AUTOSAR XML (schema 4-2-2)
package /STELLANTIS/EPT/SASWCs
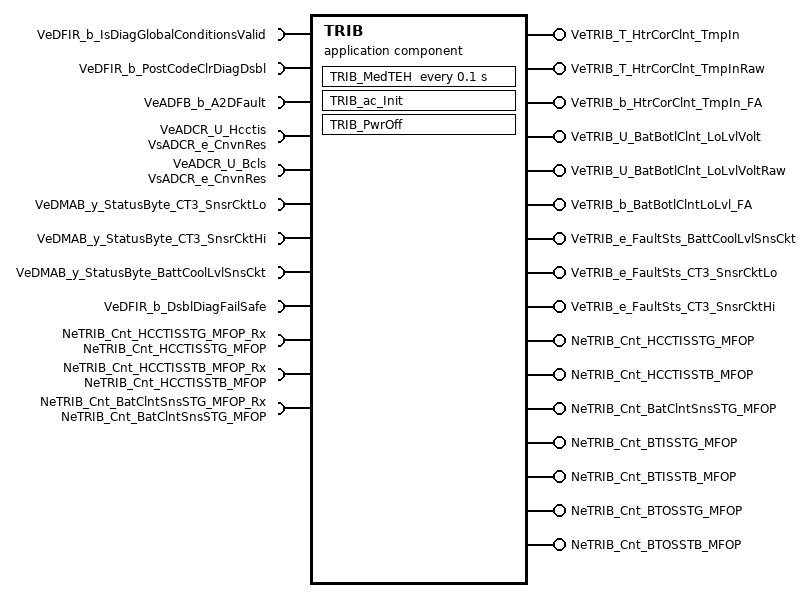
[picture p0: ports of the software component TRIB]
  application sw component type TRIB
    9 x require port:
      VeDFIR_b_IsDiagGlobalConditionsValid: variation-point={short-label=vpVeDFIR_b_IsDiagGlobalConditionsValid, sw-syscond=1}, nonqueued-receiver-com-spec{data-element=Value, init-value=0}, required-interface=VeDFIR_b_IsDiagGlobalConditionsValid
      VeDFIR_b_PostCodeClrDiagDsbl: variation-point={short-label=vpVeDFIR_b_PostCodeClrDiagDsbl, sw-syscond=1}, nonqueued-receiver-com-spec{data-element=Value, init-value=0}, required-interface=VeDFIR_b_PostCodeClrDiagDsbl
      VeADFB_b_A2DFault: variation-point={short-label=vpVeADFB_b_A2DFault, sw-syscond=1}, nonqueued-receiver-com-spec{data-element=Value, init-value=0}, required-interface=VeADFB_b_A2DFault
      VeADCR_U_Hcctis: variation-point={short-label=vpVeADCR_U_Hcctis, sw-syscond=1}, nonqueued-receiver-com-spec{data-element=VsADCR_e_CnvnRes, init-value={short-label=DefaultInitValue_IDTRAdcInpResData, fields=[0, 0]}}, required-interface=VsADCR_e_CnvnRes
      VeADCR_U_Bcls: variation-point={short-label=vpVeADCR_U_Bcls, sw-syscond=1}, nonqueued-receiver-com-spec{data-element=VsADCR_e_CnvnRes, init-value={short-label=DefaultInitValue_IDTRAdcInpResData, fields=[0, 0]}}, required-interface=VsADCR_e_CnvnRes
      VeDMAB_y_StatusByte_CT3_SnsrCktLo: variation-point={short-label=vpVeDMAB_y_StatusByte_CT3_SnsrCktLo, sw-syscond=1}, nonqueued-receiver-com-spec{data-element=Value, init-value=0}, required-interface=VeDMAB_y_StatusByte_CT3_SnsrCktLo
      VeDMAB_y_StatusByte_CT3_SnsrCktHi: variation-point={short-label=vpVeDMAB_y_StatusByte_CT3_SnsrCktHi, sw-syscond=1}, nonqueued-receiver-com-spec{data-element=Value, init-value=0}, required-interface=VeDMAB_y_StatusByte_CT3_SnsrCktHi
      VeDMAB_y_StatusByte_BattCoolLvlSnsCkt: variation-point={short-label=vpVeDMAB_y_StatusByte_BattCoolLvlSnsCkt, sw-syscond=1}, nonqueued-receiver-com-spec{data-element=Value, init-value=0}, required-interface=VeDMAB_y_StatusByte_BattCoolLvlSnsCkt
      VeDFIR_b_DsblDiagFailSafe: variation-point={short-label=vpVeDFIR_b_DsblDiagFailSafe, sw-syscond=1}, nonqueued-receiver-com-spec{data-element=Value, init-value=0}, required-interface=VeDFIR_b_DsblDiagFailSafe
    9 x provide port:
      VeTRIB_T_HtrCorClnt_TmpIn: variation-point={short-label=vpVeTRIB_T_HtrCorClnt_TmpIn, sw-syscond=1}, nonqueued-sender-com-spec{data-element=Value, init-value=0}, provided-interface=VeTRIB_T_HtrCorClnt_TmpIn
      VeTRIB_T_HtrCorClnt_TmpInRaw: variation-point={short-label=vpVeTRIB_T_HtrCorClnt_TmpInRaw, sw-syscond=1}, nonqueued-sender-com-spec{data-element=Value, init-value=0}, provided-interface=VeTRIB_T_HtrCorClnt_TmpInRaw
      VeTRIB_b_HtrCorClnt_TmpIn_FA: variation-point={short-label=vpVeTRIB_b_HtrCorClnt_TmpIn_FA, sw-syscond=1}, nonqueued-sender-com-spec{data-element=Value, init-value=0}, provided-interface=VeTRIB_b_HtrCorClnt_TmpIn_FA
      VeTRIB_U_BatBotlClnt_LoLvlVolt: variation-point={short-label=vpVeTRIB_U_BatBotlClnt_LoLvlVolt, sw-syscond=1}, nonqueued-sender-com-spec{data-element=Value, init-value=0}, provided-interface=VeTRIB_U_BatBotlClnt_LoLvlVolt
      VeTRIB_U_BatBotlClnt_LoLvlVoltRaw: variation-point={short-label=vpVeTRIB_U_BatBotlClnt_LoLvlVoltRaw, sw-syscond=1}, nonqueued-sender-com-spec{data-element=Value, init-value=0}, provided-interface=VeTRIB_U_BatBotlClnt_LoLvlVoltRaw
      VeTRIB_b_BatBotlClntLoLvl_FA: variation-point={short-label=vpVeTRIB_b_BatBotlClntLoLvl_FA, sw-syscond=1}, nonqueued-sender-com-spec{data-element=Value, init-value=0}, provided-interface=VeTRIB_b_BatBotlClntLoLvl_FA
      VeTRIB_e_FaultSts_BattCoolLvlSnsCkt: variation-point={short-label=vpVeTRIB_e_FaultSts_BattCoolLvlSnsCkt, sw-syscond=1}, nonqueued-sender-com-spec{data-element=Value, init-value=CeDFIB_e_Init}, provided-interface=VeTRIB_e_FaultSts_BattCoolLvlSnsCkt
      VeTRIB_e_FaultSts_CT3_SnsrCktLo: variation-point={short-label=vpVeTRIB_e_FaultSts_CT3_SnsrCktLo, sw-syscond=1}, nonqueued-sender-com-spec{data-element=Value, init-value=CeDFIB_e_Init}, provided-interface=VeTRIB_e_FaultSts_CT3_SnsrCktLo
      VeTRIB_e_FaultSts_CT3_SnsrCktHi: variation-point={short-label=vpVeTRIB_e_FaultSts_CT3_SnsrCktHi, sw-syscond=1}, nonqueued-sender-com-spec{data-element=Value, init-value=CeDFIB_e_Init}, provided-interface=VeTRIB_e_FaultSts_CT3_SnsrCktHi
    require port NeTRIB_Cnt_HCCTISSTG_MFOP_Rx: variation-point={short-label=vpNeTRIB_Cnt_HCCTISSTG_MFOP_Rx, sw-syscond=1}, nv-require-com-spec{init-value=0, variable=NeTRIB_Cnt_HCCTISSTG_MFOP}, required-interface=NeTRIB_Cnt_HCCTISSTG_MFOP
    require port NeTRIB_Cnt_HCCTISSTB_MFOP_Rx: variation-point={short-label=vpNeTRIB_Cnt_HCCTISSTB_MFOP_Rx, sw-syscond=1}, nv-require-com-spec{init-value=0, variable=NeTRIB_Cnt_HCCTISSTB_MFOP}, required-interface=NeTRIB_Cnt_HCCTISSTB_MFOP
    require port NeTRIB_Cnt_BatClntSnsSTG_MFOP_Rx: variation-point={short-label=vpNeTRIB_Cnt_BatClntSnsSTG_MFOP_Rx, sw-syscond=1}, nv-require-com-spec{init-value=0, variable=NeTRIB_Cnt_BatClntSnsSTG_MFOP}, required-interface=NeTRIB_Cnt_BatClntSnsSTG_MFOP
    7 x provide port:
      NeTRIB_Cnt_HCCTISSTG_MFOP: nv-provide-com-spec{ram-block-init-value=0, variable=NeTRIB_Cnt_HCCTISSTG_MFOP}, provided-interface=NeTRIB_Cnt_HCCTISSTG_MFOP
      NeTRIB_Cnt_HCCTISSTB_MFOP: nv-provide-com-spec{ram-block-init-value=0, variable=NeTRIB_Cnt_HCCTISSTB_MFOP}, provided-interface=NeTRIB_Cnt_HCCTISSTB_MFOP
      NeTRIB_Cnt_BatClntSnsSTG_MFOP: nv-provide-com-spec{ram-block-init-value=0, variable=NeTRIB_Cnt_BatClntSnsSTG_MFOP}, provided-interface=NeTRIB_Cnt_BatClntSnsSTG_MFOP
      NeTRIB_Cnt_BTISSTG_MFOP: nv-provide-com-spec{ram-block-init-value=0, variable=NeTRIB_Cnt_BTISSTG_MFOP}, provided-interface=NeTRIB_Cnt_BTISSTG_MFOP
      NeTRIB_Cnt_BTISSTB_MFOP: nv-provide-com-spec{ram-block-init-value=0, variable=NeTRIB_Cnt_BTISSTB_MFOP}, provided-interface=NeTRIB_Cnt_BTISSTB_MFOP
      NeTRIB_Cnt_BTOSSTG_MFOP: nv-provide-com-spec{ram-block-init-value=0, variable=NeTRIB_Cnt_BTOSSTG_MFOP}, provided-interface=NeTRIB_Cnt_BTOSSTG_MFOP
      NeTRIB_Cnt_BTOSSTB_MFOP: nv-provide-com-spec{ram-block-init-value=0, variable=NeTRIB_Cnt_BTOSSTB_MFOP}, provided-interface=NeTRIB_Cnt_BTOSSTB_MFOP
    behavior IB_TRIB: data-type-mapping=[msADTtoIDTMapping, ADTtoIDTMapping], handle-termination-and-restart=NO-SUPPORT
      timing event Event_MedTEH: start-on-event=TRIB_MedTEH, period=0.1
      init event Event_TRIB_ac_Init: start-on-event=TRIB_ac_Init
      init event Event_PwrOff: start-on-event=TRIB_PwrOff
      runnable TRIB_ac_Init
        data-receive-point-by-arguments:
          access IN_NeTRIB_Cnt_BatClntSnsSTG_MFOP_Rx_NeTRIB_Cnt_BatClntSnsSTG_MFOP: accessed-variable=NeTRIB_Cnt_BatClntSnsSTG_MFOP_Rx.NeTRIB_Cnt_BatClntSnsSTG_MFOP, variation-point={short-label=vpIN_NeTRIB_Cnt_BatClntSnsSTG_MFOP_Rx_NeTRIB_Cnt_BatClntSnsSTG_MFOP, sw-syscond=1}
          access IN_NeTRIB_Cnt_HCCTISSTB_MFOP_Rx_NeTRIB_Cnt_HCCTISSTB_MFOP: accessed-variable=NeTRIB_Cnt_HCCTISSTB_MFOP_Rx.NeTRIB_Cnt_HCCTISSTB_MFOP, variation-point={short-label=vpIN_NeTRIB_Cnt_HCCTISSTB_MFOP_Rx_NeTRIB_Cnt_HCCTISSTB_MFOP, sw-syscond=1}
          access IN_NeTRIB_Cnt_HCCTISSTG_MFOP_Rx_NeTRIB_Cnt_HCCTISSTG_MFOP: accessed-variable=NeTRIB_Cnt_HCCTISSTG_MFOP_Rx.NeTRIB_Cnt_HCCTISSTG_MFOP, variation-point={short-label=vpIN_NeTRIB_Cnt_HCCTISSTG_MFOP_Rx_NeTRIB_Cnt_HCCTISSTG_MFOP, sw-syscond=1}
        data-send-points:
          7 x access:
            OUT_VeTRIB_T_HtrCorClnt_TmpIn_Value: accessed-variable=VeTRIB_T_HtrCorClnt_TmpIn.Value, variation-point={short-label=vpOUT_VeTRIB_T_HtrCorClnt_TmpIn_Value, sw-syscond=1}
            OUT_VeTRIB_T_HtrCorClnt_TmpInRaw_Value: accessed-variable=VeTRIB_T_HtrCorClnt_TmpInRaw.Value, variation-point={short-label=vpOUT_VeTRIB_T_HtrCorClnt_TmpInRaw_Value, sw-syscond=1}
            OUT_VeTRIB_e_FaultSts_CT3_SnsrCktLo_Value: accessed-variable=VeTRIB_e_FaultSts_CT3_SnsrCktLo.Value, variation-point={short-label=vpOUT_VeTRIB_e_FaultSts_CT3_SnsrCktLo_Value, sw-syscond=1}
            OUT_VeTRIB_e_FaultSts_CT3_SnsrCktHi_Value: accessed-variable=VeTRIB_e_FaultSts_CT3_SnsrCktHi.Value, variation-point={short-label=vpOUT_VeTRIB_e_FaultSts_CT3_SnsrCktHi_Value, sw-syscond=1}
            OUT_VeTRIB_U_BatBotlClnt_LoLvlVolt_Value: accessed-variable=VeTRIB_U_BatBotlClnt_LoLvlVolt.Value, variation-point={short-label=vpOUT_VeTRIB_U_BatBotlClnt_LoLvlVolt_Value, sw-syscond=1}
            OUT_VeTRIB_U_BatBotlClnt_LoLvlVoltRaw_Value: accessed-variable=VeTRIB_U_BatBotlClnt_LoLvlVoltRaw.Value, variation-point={short-label=vpOUT_VeTRIB_U_BatBotlClnt_LoLvlVoltRaw_Value, sw-syscond=1}
            OUT_VeTRIB_e_FaultSts_BattCoolLvlSnsCkt_Value: accessed-variable=VeTRIB_e_FaultSts_BattCoolLvlSnsCkt.Value, variation-point={short-label=vpOUT_VeTRIB_e_FaultSts_BattCoolLvlSnsCkt_Value, sw-syscond=1}
      runnable TRIB_MedTEH
        data-receive-point-by-arguments:
          9 x access:
            IN_VeADCR_U_Bcls_VsADCR_e_CnvnRes: accessed-variable=VeADCR_U_Bcls.VsADCR_e_CnvnRes, variation-point={short-label=vpIN_VeADCR_U_Bcls_VsADCR_e_CnvnRes, sw-syscond=1}
            IN_VeADCR_U_Hcctis_VsADCR_e_CnvnRes: accessed-variable=VeADCR_U_Hcctis.VsADCR_e_CnvnRes, variation-point={short-label=vpIN_VeADCR_U_Hcctis_VsADCR_e_CnvnRes, sw-syscond=1}
            IN_VeADFB_b_A2DFault_Value: accessed-variable=VeADFB_b_A2DFault.Value, variation-point={short-label=vpIN_VeADFB_b_A2DFault_Value, sw-syscond=1}
            IN_VeDFIR_b_DsblDiagFailSafe_Value: accessed-variable=VeDFIR_b_DsblDiagFailSafe.Value, variation-point={short-label=vpIN_VeDFIR_b_DsblDiagFailSafe_Value, sw-syscond=1}
            IN_VeDFIR_b_IsDiagGlobalConditionsValid_Value: accessed-variable=VeDFIR_b_IsDiagGlobalConditionsValid.Value, variation-point={short-label=vpIN_VeDFIR_b_IsDiagGlobalConditionsValid_Value, sw-syscond=1}
            IN_VeDFIR_b_PostCodeClrDiagDsbl_Value: accessed-variable=VeDFIR_b_PostCodeClrDiagDsbl.Value, variation-point={short-label=vpIN_VeDFIR_b_PostCodeClrDiagDsbl_Value, sw-syscond=1}
            IN_VeDMAB_y_StatusByte_BattCoolLvlSnsCkt_Value: accessed-variable=VeDMAB_y_StatusByte_BattCoolLvlSnsCkt.Value, variation-point={short-label=vpIN_VeDMAB_y_StatusByte_BattCoolLvlSnsCkt_Value, sw-syscond=1}
            IN_VeDMAB_y_StatusByte_CT3_SnsrCktHi_Value: accessed-variable=VeDMAB_y_StatusByte_CT3_SnsrCktHi.Value, variation-point={short-label=vpIN_VeDMAB_y_StatusByte_CT3_SnsrCktHi_Value, sw-syscond=1}
            IN_VeDMAB_y_StatusByte_CT3_SnsrCktLo_Value: accessed-variable=VeDMAB_y_StatusByte_CT3_SnsrCktLo.Value, variation-point={short-label=vpIN_VeDMAB_y_StatusByte_CT3_SnsrCktLo_Value, sw-syscond=1}
        data-send-points:
          9 x access:
            OUT_VeTRIB_b_HtrCorClnt_TmpIn_FA_Value: accessed-variable=VeTRIB_b_HtrCorClnt_TmpIn_FA.Value, variation-point={short-label=vpOUT_VeTRIB_b_HtrCorClnt_TmpIn_FA_Value, sw-syscond=1}
            OUT_VeTRIB_T_HtrCorClnt_TmpInRaw_Value: accessed-variable=VeTRIB_T_HtrCorClnt_TmpInRaw.Value, variation-point={short-label=vpOUT_VeTRIB_T_HtrCorClnt_TmpInRaw_Value, sw-syscond=1}
            OUT_VeTRIB_T_HtrCorClnt_TmpIn_Value: accessed-variable=VeTRIB_T_HtrCorClnt_TmpIn.Value, variation-point={short-label=vpOUT_VeTRIB_T_HtrCorClnt_TmpIn_Value, sw-syscond=1}
            OUT_VeTRIB_b_BatBotlClntLoLvl_FA_Value: accessed-variable=VeTRIB_b_BatBotlClntLoLvl_FA.Value, variation-point={short-label=vpOUT_VeTRIB_b_BatBotlClntLoLvl_FA_Value, sw-syscond=1}
            OUT_VeTRIB_U_BatBotlClnt_LoLvlVoltRaw_Value: accessed-variable=VeTRIB_U_BatBotlClnt_LoLvlVoltRaw.Value, variation-point={short-label=vpOUT_VeTRIB_U_BatBotlClnt_LoLvlVoltRaw_Value, sw-syscond=1}
            OUT_VeTRIB_U_BatBotlClnt_LoLvlVolt_Value: accessed-variable=VeTRIB_U_BatBotlClnt_LoLvlVolt.Value, variation-point={short-label=vpOUT_VeTRIB_U_BatBotlClnt_LoLvlVolt_Value, sw-syscond=1}
            OUT_VeTRIB_e_FaultSts_CT3_SnsrCktLo_Value: accessed-variable=VeTRIB_e_FaultSts_CT3_SnsrCktLo.Value, variation-point={short-label=vpOUT_VeTRIB_e_FaultSts_CT3_SnsrCktLo_Value, sw-syscond=1}
            OUT_VeTRIB_e_FaultSts_BattCoolLvlSnsCkt_Value: accessed-variable=VeTRIB_e_FaultSts_BattCoolLvlSnsCkt.Value, variation-point={short-label=vpOUT_VeTRIB_e_FaultSts_BattCoolLvlSnsCkt_Value, sw-syscond=1}
            OUT_VeTRIB_e_FaultSts_CT3_SnsrCktHi_Value: accessed-variable=VeTRIB_e_FaultSts_CT3_SnsrCktHi.Value, variation-point={short-label=vpOUT_VeTRIB_e_FaultSts_CT3_SnsrCktHi_Value, sw-syscond=1}
      runnable TRIB_PwrOff
        data-send-points:
          7 x access:
            OUT_NeTRIB_Cnt_HCCTISSTG_MFOP_NeTRIB_Cnt_HCCTISSTG_MFOP: accessed-variable=NeTRIB_Cnt_HCCTISSTG_MFOP.NeTRIB_Cnt_HCCTISSTG_MFOP
            OUT_NeTRIB_Cnt_HCCTISSTB_MFOP_NeTRIB_Cnt_HCCTISSTB_MFOP: accessed-variable=NeTRIB_Cnt_HCCTISSTB_MFOP.NeTRIB_Cnt_HCCTISSTB_MFOP
            OUT_NeTRIB_Cnt_BatClntSnsSTG_MFOP_NeTRIB_Cnt_BatClntSnsSTG_MFOP: accessed-variable=NeTRIB_Cnt_BatClntSnsSTG_MFOP.NeTRIB_Cnt_BatClntSnsSTG_MFOP
            OUT_NeTRIB_Cnt_BTISSTG_MFOP_NeTRIB_Cnt_BTISSTG_MFOP: accessed-variable=NeTRIB_Cnt_BTISSTG_MFOP.NeTRIB_Cnt_BTISSTG_MFOP
            OUT_NeTRIB_Cnt_BTISSTB_MFOP_NeTRIB_Cnt_BTISSTB_MFOP: accessed-variable=NeTRIB_Cnt_BTISSTB_MFOP.NeTRIB_Cnt_BTISSTB_MFOP
            OUT_NeTRIB_Cnt_BTOSSTG_MFOP_NeTRIB_Cnt_BTOSSTG_MFOP: accessed-variable=NeTRIB_Cnt_BTOSSTG_MFOP.NeTRIB_Cnt_BTOSSTG_MFOP
            OUT_NeTRIB_Cnt_BTOSSTB_MFOP_NeTRIB_Cnt_BTOSSTB_MFOP: accessed-variable=NeTRIB_Cnt_BTOSSTB_MFOP.NeTRIB_Cnt_BTOSSTB_MFOP
      4 x variation point proxy, all with category=CONDITION:
        Variant_TRIB_BTIS_Presence: condition-access=0
        Variant_TRIB_BTOS_Presence: condition-access=0
        Variant_TRIB_BatClntSns_Presence: condition-access=1
        Variant_TRIB_HCCTIS_Presence: condition-access=1
